# soc-perf-c809403 register map
Vendor: litex
Registers are 32-bit, read-write, reset 0x0 unless marked. A register's access mark holds for its fields unless they carry their own. Offsets are from the block's base; [hi:lo] are bit positions; {n}, {i} and the like mark numbered series.

## TIMER0
Base 0xF0001000
0x00 LOAD — Load value when Timer is (re-)enabled. In One-Shot mode, the value written to this register specifies the Timer's duration in clock cycles.
0x04 RELOAD — Reload value when Timer reaches ``0``. In Periodic mode, the value written to this register specify the Timer's period in clock cycles.
0x08 EN — Enable flag of the Timer. Set this flag to ``1`` to enable/start the Timer. Set to ``0`` to disable the Timer.
  [0] en
0x0C EV_STATUS — This register contains the current raw level of the zero event trigger. Writes to this register have no effect.
  [0] zero — Level of the ``zero`` event
0x10 EV_PENDING — When a zero event occurs, the corresponding bit will be set in this register. To clear the Event, set the corresponding bit in this register.
  [0] zero — `1` if a `zero` event occurred. This Event is triggered on a **falling** edge.
0x14 EV_ENABLE — This register enables the corresponding zero events. Write a ``0`` to this register to disable individual events.
  [0] zero — Write a ``1`` to enable the ``zero`` Event

## CRG
Base 0xF0002000
0x00 MMCM_DRP_RESET
  [0] mmcm_drp_reset
0x04 MMCM_DRP_LOCKED
  [0] mmcm_drp_locked
0x08 MMCM_DRP_READ
  [0] mmcm_drp_read
0x0C MMCM_DRP_WRITE
  [0] mmcm_drp_write
0x10 MMCM_DRP_DRDY
  [0] mmcm_drp_drdy
0x14 MMCM_DRP_ADR
  [6:0] mmcm_drp_adr
0x18 MMCM_DRP_DAT_W
  [15:0] mmcm_drp_dat_w
0x1C MMCM_DRP_DAT_R
  [15:0] mmcm_drp_dat_r

## GPIO
Base 0xF0003000
0x00 OUTPUT — Values to appear on GPIO when respective `drive` bit is asserted
  [7:0] output
0x04 INPUT — Value measured on the respective GPIO pin
  [7:0] input
0x08 DRIVE — When a bit is set to `1`, the respective pad drives its value out
  [7:0] drive
0x0C INTENA — Enable interrupts when a respective bit is set
  [7:0] intena
0x10 INTPOL — When a bit is `1`, falling-edges cause interrupts. Otherwise, rising edges cause interrupts.
  [7:0] intpol
0x14 UARTSEL — Used to select which UART is routed to physical pins, 00 = kernel debug, 01 = console, others reserved based on build
  [1:0] uartsel
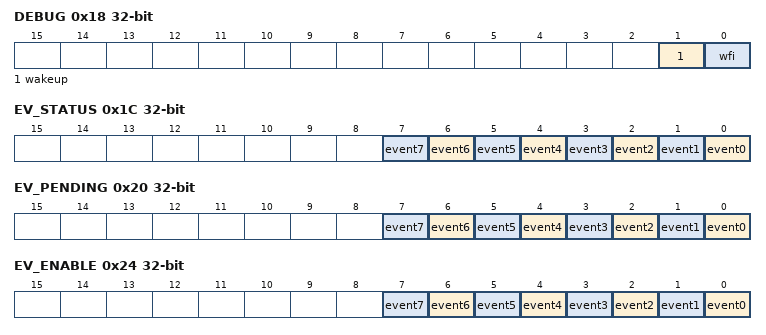
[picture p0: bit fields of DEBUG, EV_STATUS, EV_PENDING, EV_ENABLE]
0x18 DEBUG — Various debugging configurations
  [1] wakeup — Whet set, patches wakeup signal into GPIO1 instead of the usual data line. Must configure as output for the value to appear on the pin
  [0] wfi — Whet set, patches CRG powerdown into GPIO0 instead of the usual data line. Must configure as output for the value to appear on the pin
0x1C EV_STATUS — This register contains the current raw level of the event7 event trigger. Writes to this register have no effect.
  [n] event{n} (n=0..7) — Level of the ``event{n}`` event
0x20 EV_PENDING — When a event7 event occurs, the corresponding bit will be set in this register. To clear the Event, set the corresponding bit in this register.
  [n] event{n} (n=0..7) — `1` if a this particular event occurred. This Event is triggered on a **rising** edge.
0x24 EV_ENABLE — This register enables the corresponding event7 events. Write a ``0`` to this register to disable individual events.
  [n] event{n} (n=0..7) — Write a ``1`` to enable the ``event{n}`` Event

## UART
Base 0xF0005000
Same registers: CONSOLE 0xF0007000, APP_UART 0xF0009000
0x00 RXTX
  [7:0] rxtx
0x04 TXFULL — TX FIFO Full.
  [0] txfull
0x08 RXEMPTY — RX FIFO Empty.
  [0] rxempty
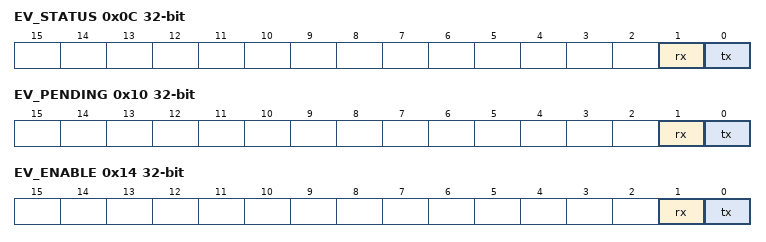
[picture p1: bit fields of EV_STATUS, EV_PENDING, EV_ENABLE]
0x0C EV_STATUS — This register contains the current raw level of the rx event trigger. Writes to this register have no effect.
  [1] rx — Level of the ``rx`` event
  [0] tx — Level of the ``tx`` event
0x10 EV_PENDING — When a rx event occurs, the corresponding bit will be set in this register. To clear the Event, set the corresponding bit in this register.
  [1] rx — `1` if a `rx` event occurred. This Event is triggered on a **falling** edge.
  [0] tx — `1` if a `tx` event occurred. This Event is triggered on a **falling** edge.
0x14 EV_ENABLE — This register enables the corresponding rx events. Write a ``0`` to this register to disable individual events.
  [1] rx — Write a ``1`` to enable the ``rx`` Event
  [0] tx — Write a ``1`` to enable the ``tx`` Event
0x18 TXEMPTY — TX FIFO Empty.
  [0] txempty
0x1C RXFULL — RX FIFO Full.
  [0] rxfull
